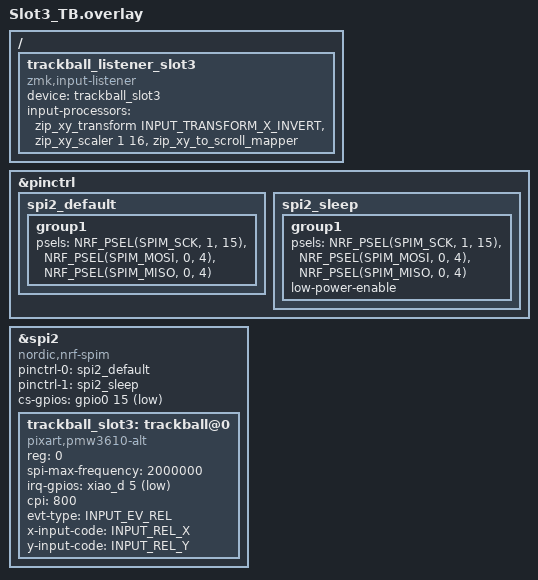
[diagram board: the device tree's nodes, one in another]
&pinctrl {
    spi2_default: spi2_default {
        group1 {
            psels = <NRF_PSEL(SPIM_SCK,  1, 15)>,
                    <NRF_PSEL(SPIM_MOSI, 0, 4)>,
                    <NRF_PSEL(SPIM_MISO, 0, 4)>;
        };
    };

    spi2_sleep: spi2_sleep {
        group1 {
            psels = <NRF_PSEL(SPIM_SCK,  1, 15)>,
                    <NRF_PSEL(SPIM_MOSI, 0, 4)>,
                    <NRF_PSEL(SPIM_MISO, 0, 4)>;
            low-power-enable;
        };
    };
};

/ {
    trackball_listener_slot3: trackball_listener_slot3 {
        compatible = "zmk,input-listener";
        device = <&trackball_slot3>;
        status = "okay";
        input-processors = <&zip_xy_transform INPUT_TRANSFORM_X_INVERT>, <&zip_xy_scaler 1 16>, <&zip_xy_to_scroll_mapper>;
    };
};

&spi2 {
    status = "okay";
    compatible = "nordic,nrf-spim";
    pinctrl-0 = <&spi2_default>;
    pinctrl-1 = <&spi2_sleep>;
    pinctrl-names = "default", "sleep";
    cs-gpios = <&gpio0 15 GPIO_ACTIVE_LOW>;

    trackball_slot3: trackball@0 {
        status = "okay";
        compatible = "pixart,pmw3610-alt";
        reg = <0>;
        spi-max-frequency = <2000000>;
        irq-gpios = <&xiao_d 5 (GPIO_ACTIVE_LOW | GPIO_PULL_UP)>;
        cpi = <800>;
        evt-type = <INPUT_EV_REL>;
        x-input-code = <INPUT_REL_X>;
        y-input-code = <INPUT_REL_Y>;
    };
};
